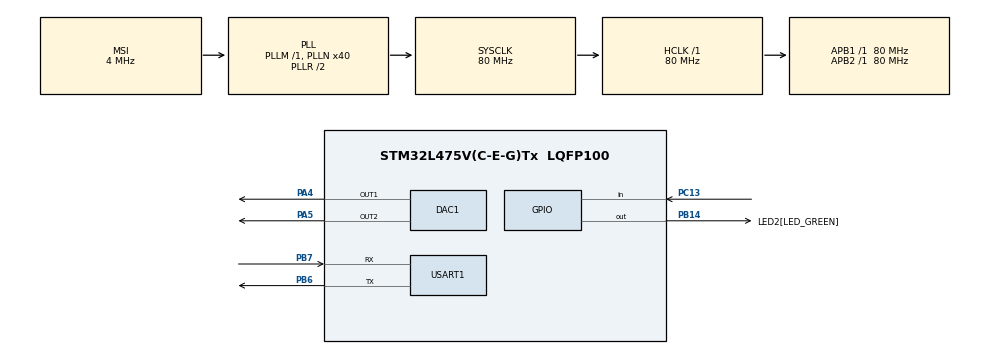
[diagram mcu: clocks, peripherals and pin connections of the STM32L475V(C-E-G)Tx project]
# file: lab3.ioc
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ADC1.Channel-0\#ChannelRegularConversion=ADC_CHANNEL_TEMPSENSOR
ADC1.NbrOfConversionFlag=1
ADC1.OffsetNumber-0\#ChannelRegularConversion=ADC_OFFSET_NONE
ADC1.Rank-0\#ChannelRegularConversion=1
ADC1.SamplingTime-0\#ChannelRegularConversion=ADC_SAMPLETIME_2CYCLES_5
ADC1.master=1
DAC1.DAC_Channel-DAC_OUT2=DAC_CHANNEL_2
Dma.Request0=USART1_RX
Dma.Request1=USART1_TX
Dma.USART1_RX.0.Direction=DMA_PERIPH_TO_MEMORY
Dma.USART1_RX.0.Instance=DMA1_Channel5
Dma.USART1_RX.0.MemDataAlignment=DMA_MDATAALIGN_BYTE
Dma.USART1_RX.0.MemInc=DMA_MINC_ENABLE
Dma.USART1_RX.0.Mode=DMA_NORMAL
Dma.USART1_RX.0.PeriphDataAlignment=DMA_PDATAALIGN_BYTE
Dma.USART1_RX.0.PeriphInc=DMA_PINC_DISABLE
Dma.USART1_RX.0.Priority=DMA_PRIORITY_LOW
Dma.USART1_TX.1.Direction=DMA_MEMORY_TO_PERIPH
Dma.USART1_TX.1.Instance=DMA1_Channel4
Dma.USART1_TX.1.MemDataAlignment=DMA_MDATAALIGN_BYTE
Dma.USART1_TX.1.MemInc=DMA_MINC_ENABLE
Dma.USART1_TX.1.Mode=DMA_NORMAL
Dma.USART1_TX.1.PeriphDataAlignment=DMA_PDATAALIGN_BYTE
Dma.USART1_TX.1.PeriphInc=DMA_PINC_DISABLE
Dma.USART1_TX.1.Priority=DMA_PRIORITY_LOW
Mcu.Family=STM32L4
Mcu.Name=STM32L475V(C-E-G)Tx
Mcu.Package=LQFP100
NVIC.DMA1_Channel4_IRQn=true\:0\:0\:false\:false\:true\:false\:true
NVIC.DMA1_Channel5_IRQn=true\:0\:0\:false\:false\:true\:false\:true
NVIC.PriorityGroup=NVIC_PRIORITYGROUP_4
PA4.Signal=COMP_DAC11_group
PA5.Signal=COMP_DAC12_group
PB14.GPIO_Label=LED2[LED_GREEN]
PB14.Signal=GPIO_Output
PB6.Mode=Asynchronous
PB6.Signal=USART1_TX
PB7.Mode=Asynchronous
PB7.Signal=USART1_RX
PC13.Signal=GPIO_Input
ProjectManager.HeapSize=0x200
ProjectManager.StackSize=0x400
ProjectManager.TargetToolchain=MDK-ARM V5
RCC.ADCFreq_Value=48000000
RCC.AHBFreq_Value=80000000
RCC.APB1Freq_Value=80000000
RCC.APB1TimFreq_Value=80000000
RCC.APB2Freq_Value=80000000
RCC.APB2TimFreq_Value=80000000
RCC.CortexFreq_Value=80000000
RCC.HCLKFreq_Value=80000000
RCC.HSE_VALUE=8000000
RCC.HSI_VALUE=16000000
RCC.MSI_VALUE=4000000
RCC.PLLN=40
RCC.PLLSAI1N=24
RCC.SYSCLKFreq_VALUE=80000000
RCC.SYSCLKSource=RCC_SYSCLKSOURCE_PLLCLK
RCC.USBFreq_Value=48000000
RCC.VCOOutputFreq_Value=160000000
SH.COMP_DAC11_group.0=DAC1_OUT1,DAC_OUT1
SH.COMP_DAC12_group.0=DAC1_OUT2,DAC_OUT2
USART1.VirtualMode-Asynchronous=VM_ASYNC
VP_ADC1_TempSens_Input.Mode=IN-TempSens
board=B-L475E-IOT01A

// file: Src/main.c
/* USER CODE BEGIN Header */
/**
  ******************************************************************************
  * @file           : main.c
  * @brief          : Main program body
  ******************************************************************************
  * @attention
  *
  * <h2><center>&copy; Copyright (c) 2020 STMicroelectronics.
  * All rights reserved.</center></h2>
  *
  * This software component is licensed by ST under BSD 3-Clause license,
  * the "License"; You may not use this file except in compliance with the
  * License. You may obtain a copy of the License at:
  *                        opensource.org/licenses/BSD-3-Clause
  *
  ******************************************************************************
  */
/* USER CODE END Header */

#include "main.h"
#include "stm32l4xx_hal.h"

ADC_HandleTypeDef hadc1;

DAC_HandleTypeDef hdac1;

UART_HandleTypeDef huart1;
DMA_HandleTypeDef hdma_usart1_rx;
DMA_HandleTypeDef hdma_usart1_tx;

void SystemClock_Config(void);
static void MX_GPIO_Init(void);
static void MX_DMA_Init(void);
static void MX_ADC1_Init(void);
static void MX_DAC1_Init(void);
static void MX_USART1_UART_Init(void);
/* USER CODE BEGIN PFP */
int UART_Print_String(UART_HandleTypeDef* huart, char* array_p, int array_len);
int UART_Print_String_DMA(UART_HandleTypeDef* huart, uint8_t* array_p, uint16_t array_size);

int ADCTemp0, ADCTemp, ones, tens;
int sys_flag;
/* USER CODE END PFP */

int main(void)
{
	char ch[5] = {'j','o','b','s','\n'};
	char tempArr[19] = {'T', 'e', 'm', 'p', 'e', 'r', 'a', 't', 'u', 'r', 'e', ' ', '=', ' ', '3', '0', ' ', 'C', '\n'};
	char dmaArr[30];
	int count = 0;

  /* MCU Configuration--------------------------------------------------------*/

  /* Reset of all peripherals, Initializes the Flash interface and the Systick. */
  HAL_Init();

  /* Configure the system clock */
  SystemClock_Config();

  /* Initialize all configured peripherals */
  MX_GPIO_Init();
  MX_DMA_Init();
  MX_ADC1_Init();
  MX_DAC1_Init();
  MX_USART1_UART_Init();
  /* USER CODE BEGIN 2 */
	//HAL_ADC_Init(&hadc1);
	HAL_ADCEx_Calibration_Start(&hadc1, ADC_SINGLE_ENDED);
	uint32_t cal2 = (int32_t)*TEMPSENSOR_CAL2_ADDR;
	//uint32_t cal1 = (int32_t)*TEMPSENSOR_CAL1_ADDR;
	HAL_ADCEx_Calibration_SetValue(&hadc1, ADC_SINGLE_ENDED, cal2);

  /* USER CODE END 2 */

  /* Infinite loop */
  /* USER CODE BEGIN WHILE */
  while (1){

		//somewhere, we need start, wait, read. There needs to be a delay between start and read or else it doesn't have time to
		//take a sample.

		//first section, using delay
		//HAL_Delay(100);
		//UART_Print_String(&huart1, &tempArr[0], 25);

		//second section, using systick
		if (sys_flag == 1) {
			sys_flag = 0;

			//__HAL_ADC_CALC_TEMPERATURE
			HAL_ADC_Start(&hadc1);

			if (HAL_ADC_PollForConversion(&hadc1, 10000) == HAL_OK) { //3000
				ADCTemp0 = HAL_ADC_GetValue(&hadc1);
				HAL_ADC_Stop(&hadc1);
				ADCTemp = __HAL_ADC_CALC_TEMPERATURE(3300, ADCTemp0, ADC_RESOLUTION_10B);

				tens = ADCTemp/10 + '0';
				ones = ADCTemp%10 + '0';
				//only DAC to UART
				/*tempArr[14] = tens;
				tempArr[15] = ones;
				UART_Print_String(&huart1, &tempArr[0], 19); */

				//DAC to DMA to UART
				if (count < 30) {
					dmaArr[count] = tens;
					dmaArr[count+1] = ones;
					dmaArr[count+2] = '\n';
					count += 3;
				}
				else {
					count = 0;
				}
				UART_Print_String_DMA(&huart1, (uint8_t*)dmaArr, 30);

			}

		}
  }
}

//Only DAC to UART
//UART = Universal Serial Receiver/Transmitter
//UART transmit using software funciton HAL_UART_Transmit()
//Must complete array transmission before excecuting other code = inefficient use of resources
int UART_Print_String(UART_HandleTypeDef* huart, char* array_p, int array_len) {
	int i;
	for (i = 0; i< array_len; i++) { //P1037 for HAL_UART_Transmit
		if (!HAL_UART_Transmit(huart, (uint8_t *)array_p, array_len, 30000)){
			return 0;
		}
	}
	return 1;
}

//Using DMA (ADC to DMA then DMA to UART)
//By enabling the DMA on the UART transmit interface
//And passing the DMA the array's start address and number of elements
//The UART can then read the entire array from memory
//This transmission only needs to be started in software
//The program can move on to other tasks while the array transmission continues in the background
int UART_Print_String_DMA(UART_HandleTypeDef* huart, uint8_t* array_p, uint16_t array_size) {
		if (HAL_UART_Transmit_DMA(huart, array_p, array_size) == HAL_OK){
			return 1;
		}
		else{
			return 0;
		}
}

void SystemClock_Config(void)
{
  RCC_OscInitTypeDef RCC_OscInitStruct = {0};
  RCC_ClkInitTypeDef RCC_ClkInitStruct = {0};
  RCC_PeriphCLKInitTypeDef PeriphClkInit = {0};

  /** Initializes the CPU, AHB and APB busses clocks
  */
  RCC_OscInitStruct.OscillatorType = RCC_OSCILLATORTYPE_MSI;
  RCC_OscInitStruct.MSIState = RCC_MSI_ON;
  RCC_OscInitStruct.MSICalibrationValue = 0;
  RCC_OscInitStruct.MSIClockRange = RCC_MSIRANGE_6;
  RCC_OscInitStruct.PLL.PLLState = RCC_PLL_ON;
  RCC_OscInitStruct.PLL.PLLSource = RCC_PLLSOURCE_MSI;
  RCC_OscInitStruct.PLL.PLLM = 1;
  RCC_OscInitStruct.PLL.PLLN = 40;
  RCC_OscInitStruct.PLL.PLLP = RCC_PLLP_DIV7;
  RCC_OscInitStruct.PLL.PLLQ = RCC_PLLQ_DIV2;
  RCC_OscInitStruct.PLL.PLLR = RCC_PLLR_DIV2;
  if (HAL_RCC_OscConfig(&RCC_OscInitStruct) != HAL_OK)
  {
    Error_Handler();
  }
  /** Initializes the CPU, AHB and APB busses clocks
  */
  RCC_ClkInitStruct.ClockType = RCC_CLOCKTYPE_HCLK|RCC_CLOCKTYPE_SYSCLK
                              |RCC_CLOCKTYPE_PCLK1|RCC_CLOCKTYPE_PCLK2;
  RCC_ClkInitStruct.SYSCLKSource = RCC_SYSCLKSOURCE_PLLCLK;
  RCC_ClkInitStruct.AHBCLKDivider = RCC_SYSCLK_DIV1;
  RCC_ClkInitStruct.APB1CLKDivider = RCC_HCLK_DIV1;
  RCC_ClkInitStruct.APB2CLKDivider = RCC_HCLK_DIV1;

  if (HAL_RCC_ClockConfig(&RCC_ClkInitStruct, FLASH_LATENCY_4) != HAL_OK)
  {
    Error_Handler();
  }
  PeriphClkInit.PeriphClockSelection = RCC_PERIPHCLK_USART1|RCC_PERIPHCLK_ADC;
  PeriphClkInit.Usart1ClockSelection = RCC_USART1CLKSOURCE_PCLK2;
  PeriphClkInit.AdcClockSelection = RCC_ADCCLKSOURCE_PLLSAI1;
  PeriphClkInit.PLLSAI1.PLLSAI1Source = RCC_PLLSOURCE_MSI;
  PeriphClkInit.PLLSAI1.PLLSAI1M = 1;
  PeriphClkInit.PLLSAI1.PLLSAI1N = 24;
  PeriphClkInit.PLLSAI1.PLLSAI1P = RCC_PLLP_DIV7;
  PeriphClkInit.PLLSAI1.PLLSAI1Q = RCC_PLLQ_DIV2;
  PeriphClkInit.PLLSAI1.PLLSAI1R = RCC_PLLR_DIV2;
  PeriphClkInit.PLLSAI1.PLLSAI1ClockOut = RCC_PLLSAI1_ADC1CLK;
  if (HAL_RCCEx_PeriphCLKConfig(&PeriphClkInit) != HAL_OK)
  {
    Error_Handler();
  }
  /** Configure the main internal regulator output voltage
  */
  if (HAL_PWREx_ControlVoltageScaling(PWR_REGULATOR_VOLTAGE_SCALE1) != HAL_OK)
  {
    Error_Handler();
  }

	    /**Configure the Systick interrupt time
    */
  HAL_SYSTICK_Config(HAL_RCC_GetHCLKFreq()/1000); //=1ms

    /**Configure the Systick
    */
  HAL_SYSTICK_CLKSourceConfig(SYSTICK_CLKSOURCE_HCLK);

  /* SysTick_IRQn interrupt configuration */
  HAL_NVIC_SetPriority(SysTick_IRQn, 0, 0); //enable interrupt
}

static void MX_ADC1_Init(void)
{

  ADC_MultiModeTypeDef multimode = {0};
  ADC_ChannelConfTypeDef sConfig = {0};

  /** Common config
  */
  hadc1.Instance = ADC1;
  hadc1.Init.ClockPrescaler = ADC_CLOCK_ASYNC_DIV1;

	//this was changed from 12B to 10B by Brandon
	hadc1.Init.Resolution = ADC_RESOLUTION_10B;
  hadc1.Init.DataAlign = ADC_DATAALIGN_RIGHT;
  hadc1.Init.ScanConvMode = ADC_SCAN_DISABLE;
  hadc1.Init.EOCSelection = ADC_EOC_SINGLE_CONV;
  hadc1.Init.LowPowerAutoWait = DISABLE;
  hadc1.Init.ContinuousConvMode = DISABLE;
  hadc1.Init.NbrOfConversion = 1;
  hadc1.Init.DiscontinuousConvMode = DISABLE;
  hadc1.Init.ExternalTrigConv = ADC_SOFTWARE_START;
  hadc1.Init.ExternalTrigConvEdge = ADC_EXTERNALTRIGCONVEDGE_NONE;
  hadc1.Init.DMAContinuousRequests = DISABLE;
  hadc1.Init.Overrun = ADC_OVR_DATA_PRESERVED;
  hadc1.Init.OversamplingMode = DISABLE;
  if (HAL_ADC_Init(&hadc1) != HAL_OK)
  {
    Error_Handler();
  }
  /** Configure the ADC multi-mode
  */
  multimode.Mode = ADC_MODE_INDEPENDENT;
  if (HAL_ADCEx_MultiModeConfigChannel(&hadc1, &multimode) != HAL_OK)
  {
    Error_Handler();
  }
  /** Configure Regular Channel
  */
  sConfig.Channel = ADC_CHANNEL_TEMPSENSOR;
  sConfig.Rank = ADC_REGULAR_RANK_1;
  sConfig.SamplingTime = ADC_SAMPLETIME_47CYCLES_5;
  sConfig.SingleDiff = ADC_SINGLE_ENDED;
  sConfig.OffsetNumber = ADC_OFFSET_NONE;
  sConfig.Offset = 0;
  if (HAL_ADC_ConfigChannel(&hadc1, &sConfig) != HAL_OK)
  {
    Error_Handler();
  }

}

static void MX_DAC1_Init(void)
{

  DAC_ChannelConfTypeDef sConfig = {0};

  /** DAC Initialization
  */
  hdac1.Instance = DAC1;
  if (HAL_DAC_Init(&hdac1) != HAL_OK)
  {
    Error_Handler();
  }
  /** DAC channel OUT1 config
  */
  sConfig.DAC_SampleAndHold = DAC_SAMPLEANDHOLD_DISABLE;
  sConfig.DAC_Trigger = DAC_TRIGGER_NONE;
  sConfig.DAC_OutputBuffer = DAC_OUTPUTBUFFER_ENABLE;
  sConfig.DAC_ConnectOnChipPeripheral = DAC_CHIPCONNECT_DISABLE;
  sConfig.DAC_UserTrimming = DAC_TRIMMING_FACTORY;
  if (HAL_DAC_ConfigChannel(&hdac1, &sConfig, DAC_CHANNEL_1) != HAL_OK)
  {
    Error_Handler();
  }
  /** DAC channel OUT2 config
  */
  sConfig.DAC_ConnectOnChipPeripheral = DAC_CHIPCONNECT_DISABLE;
  if (HAL_DAC_ConfigChannel(&hdac1, &sConfig, DAC_CHANNEL_2) != HAL_OK)
  {
    Error_Handler();
  }

}

static void MX_USART1_UART_Init(void)
{

  huart1.Instance = USART1;
  huart1.Init.BaudRate = 115200;
  huart1.Init.WordLength = UART_WORDLENGTH_8B;
  huart1.Init.StopBits = UART_STOPBITS_1;
  huart1.Init.Parity = UART_PARITY_NONE;
  huart1.Init.Mode = UART_MODE_TX_RX;
  huart1.Init.HwFlowCtl = UART_HWCONTROL_NONE;
  huart1.Init.OverSampling = UART_OVERSAMPLING_16;
  huart1.Init.OneBitSampling = UART_ONE_BIT_SAMPLE_DISABLE;
  huart1.AdvancedInit.AdvFeatureInit = UART_ADVFEATURE_NO_INIT;
  if (HAL_UART_Init(&huart1) != HAL_OK)
  {
    Error_Handler();
  }
  /* USER CODE BEGIN USART1_Init 2 */
	//for DMA
	HAL_NVIC_SetPriority(USART1_IRQn, 0, 0);
  HAL_NVIC_EnableIRQ(USART1_IRQn);
  /* USER CODE END USART1_Init 2 */

}

static void MX_DMA_Init(void)
{
  /* DMA controller clock enable */
  __HAL_RCC_DMA1_CLK_ENABLE();

  /* DMA interrupt init */
	HAL_DMA_IRQHandler(&hdma_usart1_tx);

	//link DMA handle with peripheral handle
	//copies the hdmatx field of the huart1 handle into the hdma_usart1_tx handle
	__HAL_LINKDMA(&huart1,hdmatx,hdma_usart1_tx);

  /* DMA1_Channel4_IRQn interrupt configuration */
  HAL_NVIC_SetPriority(DMA1_Channel4_IRQn, 0, 0);
  HAL_NVIC_EnableIRQ(DMA1_Channel4_IRQn);
  /* DMA1_Channel5_IRQn interrupt configuration */
  HAL_NVIC_SetPriority(DMA1_Channel5_IRQn, 0, 0);
  HAL_NVIC_EnableIRQ(DMA1_Channel5_IRQn);

}

static void MX_GPIO_Init(void)
{
  GPIO_InitTypeDef GPIO_InitStruct = {0};

  /* GPIO Ports Clock Enable */
  __HAL_RCC_GPIOC_CLK_ENABLE();
  __HAL_RCC_GPIOA_CLK_ENABLE();
  __HAL_RCC_GPIOB_CLK_ENABLE();

  /*Configure GPIO pin Output Level */
  HAL_GPIO_WritePin(LED2_GPIO_Port, LED2_Pin, GPIO_PIN_RESET);

  /*Configure GPIO pin : PC13 */
  GPIO_InitStruct.Pin = GPIO_PIN_13;
  GPIO_InitStruct.Mode = GPIO_MODE_INPUT;
  GPIO_InitStruct.Pull = GPIO_NOPULL;
  HAL_GPIO_Init(GPIOC, &GPIO_InitStruct);

  /*Configure GPIO pin : LED2_Pin */
  GPIO_InitStruct.Pin = LED2_Pin;
  GPIO_InitStruct.Mode = GPIO_MODE_OUTPUT_PP;
  GPIO_InitStruct.Pull = GPIO_NOPULL;
  GPIO_InitStruct.Speed = GPIO_SPEED_FREQ_LOW;
  HAL_GPIO_Init(LED2_GPIO_Port, &GPIO_InitStruct);

}

void Error_Handler(void)
{
}

/************************ (C) COPYRIGHT STMicroelectronics *****END OF FILE****/
